AUTOSAR XML (schema 4-2-2)
package /AUTOLIV/SoftwareComponents/LPM
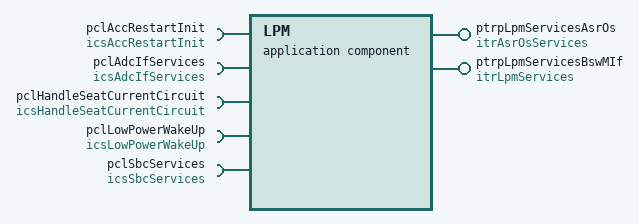
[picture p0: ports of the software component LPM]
  application sw component type LPM: category=SWC
    5 x require port:
      pclAccRestartInit: client-com-spec=RestartInitialization, required-interface=icsAccRestartInit  # # Architecture Element ID ARCH_SW_LPM_pclAccRestartInit_ACC_RestartInitialization # Description - The ACC_RestartInitialization runnable shall be called in the LPM_sleepRestore runnable in order to initialize ACC module from sleep # Data Flow # Linked Runnable - ACC_RestartInitialization #Traceability
      pclAdcIfServices: required-com-specs=[StartConversion, StopConversion, WaitForConversion], required-interface=icsAdcIfServices  # # Architecture Element ID&#xD; ARCH_SW_LPM_pclAdcIfSerrvices_AdcIf_StartConversion # Description - The AdcIf_StartConversion runnable shall be called in the LPM_sleepRestore runnable in order to start AdcIf timer # Data Flow # Linked Runnable - AdcIf_StartConversion #Traceability --------------------------------------------------------------------------------------------------------------------------------------------- # Architecture Element ID ARCH_SW_LPM_pclAdcIfSerrvices_AdcIf_StopConversion # Description - AdcIf_StopConversion runnable shall be called in the LPM_sleepInit runnable in order to stop AdcIf timer # Data Flow # Linked Runnable - AdcIf_StoptConversion #Traceability --------------------------------------------------------------------------------------------------------------------------------------------- # Architecture Element ID ARCH_SW_LPM_pclAdcIfSerrvices_AdcIf_WaitForConversion # Description - AdcIf_WaitForConversion runnable shall be called in the LPM_sleepInit runnable in order to wait for the last Adc timer trigger # Data Flow # Linked Runnable - AdcIf_WaaitForConversion #Traceability
      pclHandleSeatCurrentCircuit: client-com-spec=IoHwAb_HandleSeatCurrentCircuit, required-interface=icsHandleSeatCurrentCircuit  # # Architecture Element ID ARCH_SW_LPM_pclHandleSeatCurrentCircuit_IoHwAb_HandleSeatCurrentCircuit # Description - The IoHwAb_HandleSeatCurrentCircuit runnable shall be called in the LPM_sleepMainLoop runnable in order to control the seat/belt detection circuit # Data Flow ##Inputs {Adc value for first input} {Adc value for second input} {reset circuit state} ##Outputs {Valid values state} # Linked Runnable - LPM_sleepMainLoop #Traceability
      pclLowPowerWakeUp: client-com-spec=HandleSeatVariants, required-interface=icsLowPowerWakeUp  # # Architecture Element ID ARCH_SW_LPM_pclLowPowerwakeUp_IoHwAb_HandleSeatVariants # Description - The IoHwAb_HandleSeatVariants runnable shall be called in the LPM_sleepMainLoop runnable in order to detect seat/belt status wakeup conditions # Data Flow ##Inputs {Adc value for first input} {Adc value for second input} ##Outputs {Wakeup status} # Linked Runnable - LPM_sleepMainLoop #Traceability
      pclSbcServices: required-com-specs=[SBC_sleepTriggerWatchdog, SBC_SetToLowPower, SBC_SetToNormal], required-interface=icsSbcServices  # # Architecture Element ID ARCH_SW_LPM_pclSbcServices_SBC_SetToLowPower # Description - The SBC_SetToLowPower runnable shall be called in the LPM_sleepInit runnable in order to set the SBC to low power mode # Data Flow # Linked Runnable - LPM_sleepInit #Traceability --------------------------------------------------------------------------------------------------------------------------------------------- # Architecture Element ID ARCH_SW_LPM_pclSbcServices_SBC_sleepTriggerWatchdog # Description - The SBC_sleepTriggerWatchdog runnable shall be called in the LPM_sleepInit runnable in order to trigger the external watchdog # Data Flow # Linked Runnable - LPM_sleepInit - LPM_sleepMainLoop #Traceability --------------------------------------------------------------------------------------------------------------------------------------------- # Architecture Element ID ARCH_SW_LPM_pclSbcServices_SBC_SetToNormal # Description - The SBC_SetToNormal runnable shall be called in the LPM_sleepRestore runnable in order to set the SBC in normal mode # Data Flow # Linked Runnable - LPM_sleepRestore #Traceability
    provide port ptrpLpmServicesAsrOs: provided-interface=itrAsrOsServices  # # Architecture Element ID ARCH_SW_LPM_ptrpLpmServicesAsrOs_LPTMR_ISR # Description - The LPTMR_ISR runnable shall be called in the Os services runnable upon a hardware event in the LPTMR timer # Data Flow # Linked Runnable - LPTMR_ISR #Traceability --------------------------------------------------------------------------------------------------------------------------------------------- # Architecture Element ID ARCH_SW_LPM_ptrpLpmServicesAsrOs_PORTD_ISR # Description - The PORTD_ISR runnable shall be called in the Os services runnable upon a hardware event in the Port D module # Data Flow # Linked Runnable - PORTD_ISR #Traceability
    provide port ptrpLpmServicesBswMIf: provided-interface=itrLpmServices  # # Architecture Element ID ARCH_SW_LPM_ptrpLpmServicesBswMIf_LPM_sleepInit # Description - The LPM_sleepInit runnable shall be called in the BswM_OnLowPwrFromPostRun runnable in order to initialize LPM module # Data Flow # Linked Runnable - LPM_sleepInit #Traceability DOM_eCS_TF_P_200, DOM_eCS_TF_P_265, DOM_eCS_TF_P_205, DOM_eCS_TF_P_268 --------------------------------------------------------------------------------------------------------------------------------------------- # Architecture Element ID ARCH_SW_LPM_ptrpLpmServicesBswMIf_LPM_sleepMainLoop # Description - The LPM_sleepMainLoop runnable shall be called in the BswM_OnLowPwrFromPostRun runnable in order to enter in low power mode main loop. # Data Flow # Linked Runnable - LPM_sleepMainLoop #Traceability DOM_eCS_TF_P_200, DOM_eCS_TF_P_269, DOM_eCS_TF_P_208, DOM_eCS_TF_P_271, DOM_eCS_TF_P_214, DOM_eCS_TF_P_317 --------------------------------------------------------------------------------------------------------------------------------------------- # Architecture Element ID ARCH_SW_LPM_ptrpLpmServicesBswMIf_LPM_sleepRestore # Description - The LPM_sleepRestore runnable shall be called in the BswM_OnLowPwrFromPostRun runnable in order to restore previous state and set rules to go back in RUN STATE # Data Flow # Linked Runnable - LPM_sleepRestore #Traceability DOM_eCS_TF_P_200, DOM_eCS_TF_P_214, DOM_eCS_TF_P_317, DOM_eCS_TF_P_216
